# CM41x_M0 register map
Vendor: Analog Devices; Series: CM41x_M0; File version: 1p0
CPU: CM0 r0p0, little endian, MPU, FPU, 4 interrupt priority bits
Registers are 32-bit, read-write, reset 0x0 unless marked. A register's access mark holds for its fields unless they carry their own. Offsets are from the block's base; [hi:lo] are bit positions; {n}, {i} and the like mark numbered series.

## CRC0 — Cyclic Redundancy Check Unit
Base 0x4004C000
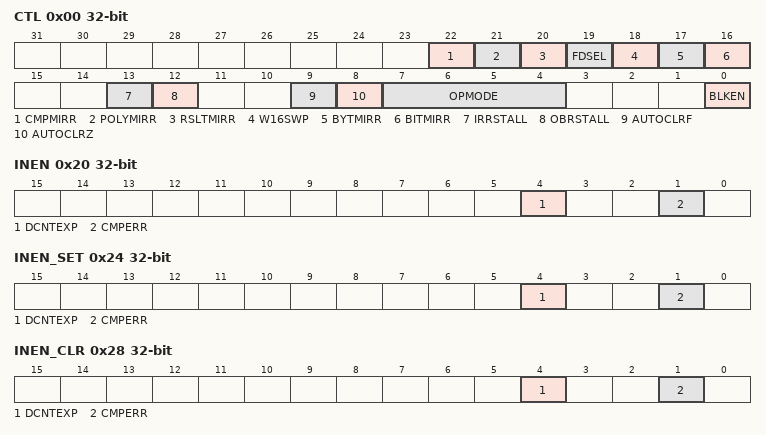
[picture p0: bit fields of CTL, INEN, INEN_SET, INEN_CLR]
0x00 CTL — Control Register
  [22] CMPMIRR — COMPARE Register Mirroring
  [21] POLYMIRR — Polynomial Register Mirroring
  [20] RSLTMIRR — Result Register Mirroring
  [19] FDSEL — FIFO Data Select
  [18] W16SWP — Word16 Swapping
  [17] BYTMIRR — Byte Mirroring
  [16] BITMIRR — Bit Mirroring
  [13] IRRSTALL — Intermediate Result Ready Stall
  [12] OBRSTALL — Output Buffer Ready Stall
  [9] AUTOCLRF — Auto Clear to One
  [8] AUTOCLRZ — Auto Clear to Zero
  [7:4] OPMODE — Operation Mode
  [0] BLKEN — Block Enable
0x04 DCNT — Data Word Count Register
  [31:0] VALUE range 0x00000000..0xFFFFFFFF — Data Word Count
0x08 DCNTRLD — Data Word Count Reload Register
  [31:0] VALUE range 0x00000000..0xFFFFFFFF — Reload Value
0x14 COMP — Data Compare Register
  [31:0] VALUE range 0x00000000..0xFFFFFFFF — Expected CRC Result Value
0x18 FILLVAL — Fill Value Register
  [31:0] VALUE range 0x00000000..0xFFFFFFFF — Memory Fill Value
0x1C DFIFO — Data FIFO Register
  [31:0] VALUE range 0x00000000..0xFFFFFFFF — Data FIFO Value
0x20 INEN — Interrupt Enable Register
  [4] DCNTEXP — Data Count Expired (Status) Interrupt Enable
    0=DCNTEXP_MSK (Disable (mask) interrupt); 1=DCNTEXP_UMSK (Enable (unmask) interrupt)
  [1] CMPERR — Compare Error Interrupt Enable
    0=CMPERR_MSK (Disable (mask) interrupt); 1=CMPERR_UMSK (Enable (unmask) interrupt)
0x24 INEN_SET — Interrupt Enable Set Register
  [4] DCNTEXP — Data Count Expired (Status) Interrupt Enable Set
  [1] CMPERR — Compare Error Interrupt
0x28 INEN_CLR — Interrupt Enable Clear Register
  [4] DCNTEXP — Data Count Expired
  [1] CMPERR — Compare Error Clear
0x2C POLY — Polynomial Register
  [31:0] VALUE range 0x00000000..0xFFFFFFFF — CRC Polynomial Value
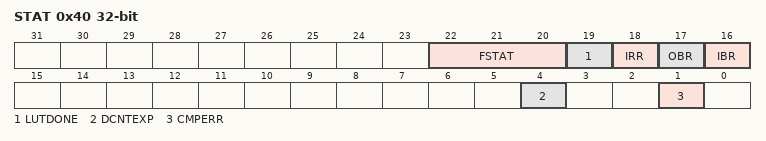
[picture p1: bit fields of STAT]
0x40 STAT — Status Register
  [22:20] FSTAT ro — FIFO Status
  [19] LUTDONE ro — Look-Up Table Done
  [18] IRR ro — Intermediate Result Ready
  [17] OBR ro — Output Buffer Ready
  [16] IBR ro — Input Buffer Ready
  [4] DCNTEXP — Data Count Expired
  [1] CMPERR — Compare Error
0x44 DCNTCAP — Data Count Capture Register
  [31:0] VALUE range 0x00000000..0xFFFFFFFF — Data Count Capture Value
0x4C RESULT_FIN — CRC Final Result Register
  [31:0] VALUE range 0x00000000..0xFFFFFFFF — Computed CRC
0x50 RESULT_CUR — CRC Current Result Register
  [31:0] VALUE range 0x00000000..0xFFFFFFFF — Intermediate CRC Result

## HAE0 — Harmonic Analysis Engine
Base 0x40050000
0xA0 RUN
  [0] RUN — Run/Stop
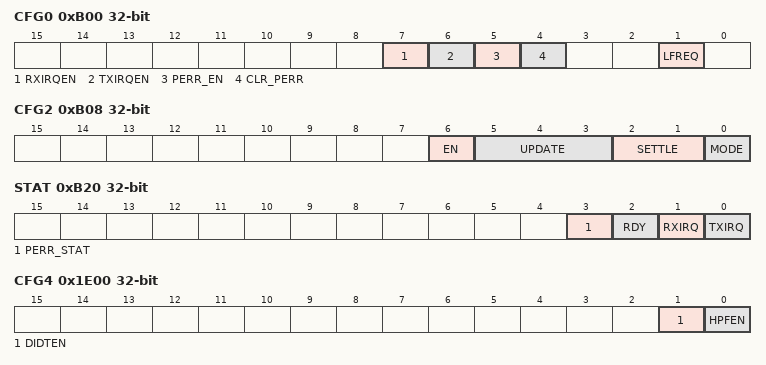
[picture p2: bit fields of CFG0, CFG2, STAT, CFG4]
0xB00 CFG0 — Configuration 0 Register
  [7] RXIRQEN — Receive IRQ Enable
  [6] TXIRQEN — Transmit IRQ Enable
  [5] PERR_EN range 0x00000000..0x00000001 — Parity Enable
  [4] CLR_PERR ro — Clear Parity Status
  [1] LFREQ — Line Frequency Select
0xB04 CFG1 — Configuration 1 Register
  [14:0] STARTDIV range 0x00000000..0x00007FFF — Start (Clock) Divider
0xB08 CFG2 — Configuration 2 Register
  [6] EN — Enable Clock
  [5:3] UPDATE — Update Rate Select
  [2:1] SETTLE — Settle Period Select
  [0] MODE — (Results) Mode Select
0xB0C CFG3 — Configuration 3 Register
  [12:0] CHANEN — Channel n Enable
0xB20 STAT — Status Register
  [3] PERR_STAT ro — Parity Error Status
  [2] RDY ro — Ready Status
  [1] RXIRQ — Receive IRQ Status
  [0] TXIRQ — Transmit IRQ Status
0xB40 ISAMPLE — I (Current) Sample Register
  [23:0] VALUE range 0x00000000..0x00FFFFFF — Current Input Sample
0xB44 VSAMPLE — V (Voltage) Sample Register
  [23:0] VALUE range 0x00000000..0x00FFFFFF — Voltage Input Sample
0xB80 IWAVEFORM — I (Current) Waveform Register
  [23:0] VALUE ro — Current Waveform
0xB84 VWAVEFORM — V (Voltage) Waveform Register
  [23:0] VALUE ro — Voltage Waveform
0x1E00 CFG4 — Configuration 4 Register
  [1] DIDTEN — di/dt (Sensor) Enable
  [0] HPFEN — High-Pass Filter Enable
0x1E04 DIDT_GAIN
  [27:0] VALUE range 0x00000000..0x0FFFFFFF — di/dt Sensor Gain
0x1E08 DIDT_COEF — DIDT Coefficient Register
  [27:0] VALUE range 0x00000000..0x0FFFFFFF — di/dt Coefficient
0x1E10 VLEVEL — Voltage Level Register
  [27:0] VALUE range 0x00000000..0x0FFFFFFF — Voltage Input Level
{0x1E2C+4i} H{i}_INDX (i=0..11) — Harmonic n Index Register
  [5:0] VALUE range 0x00000000..0x0000003F — Harmonic n Index
